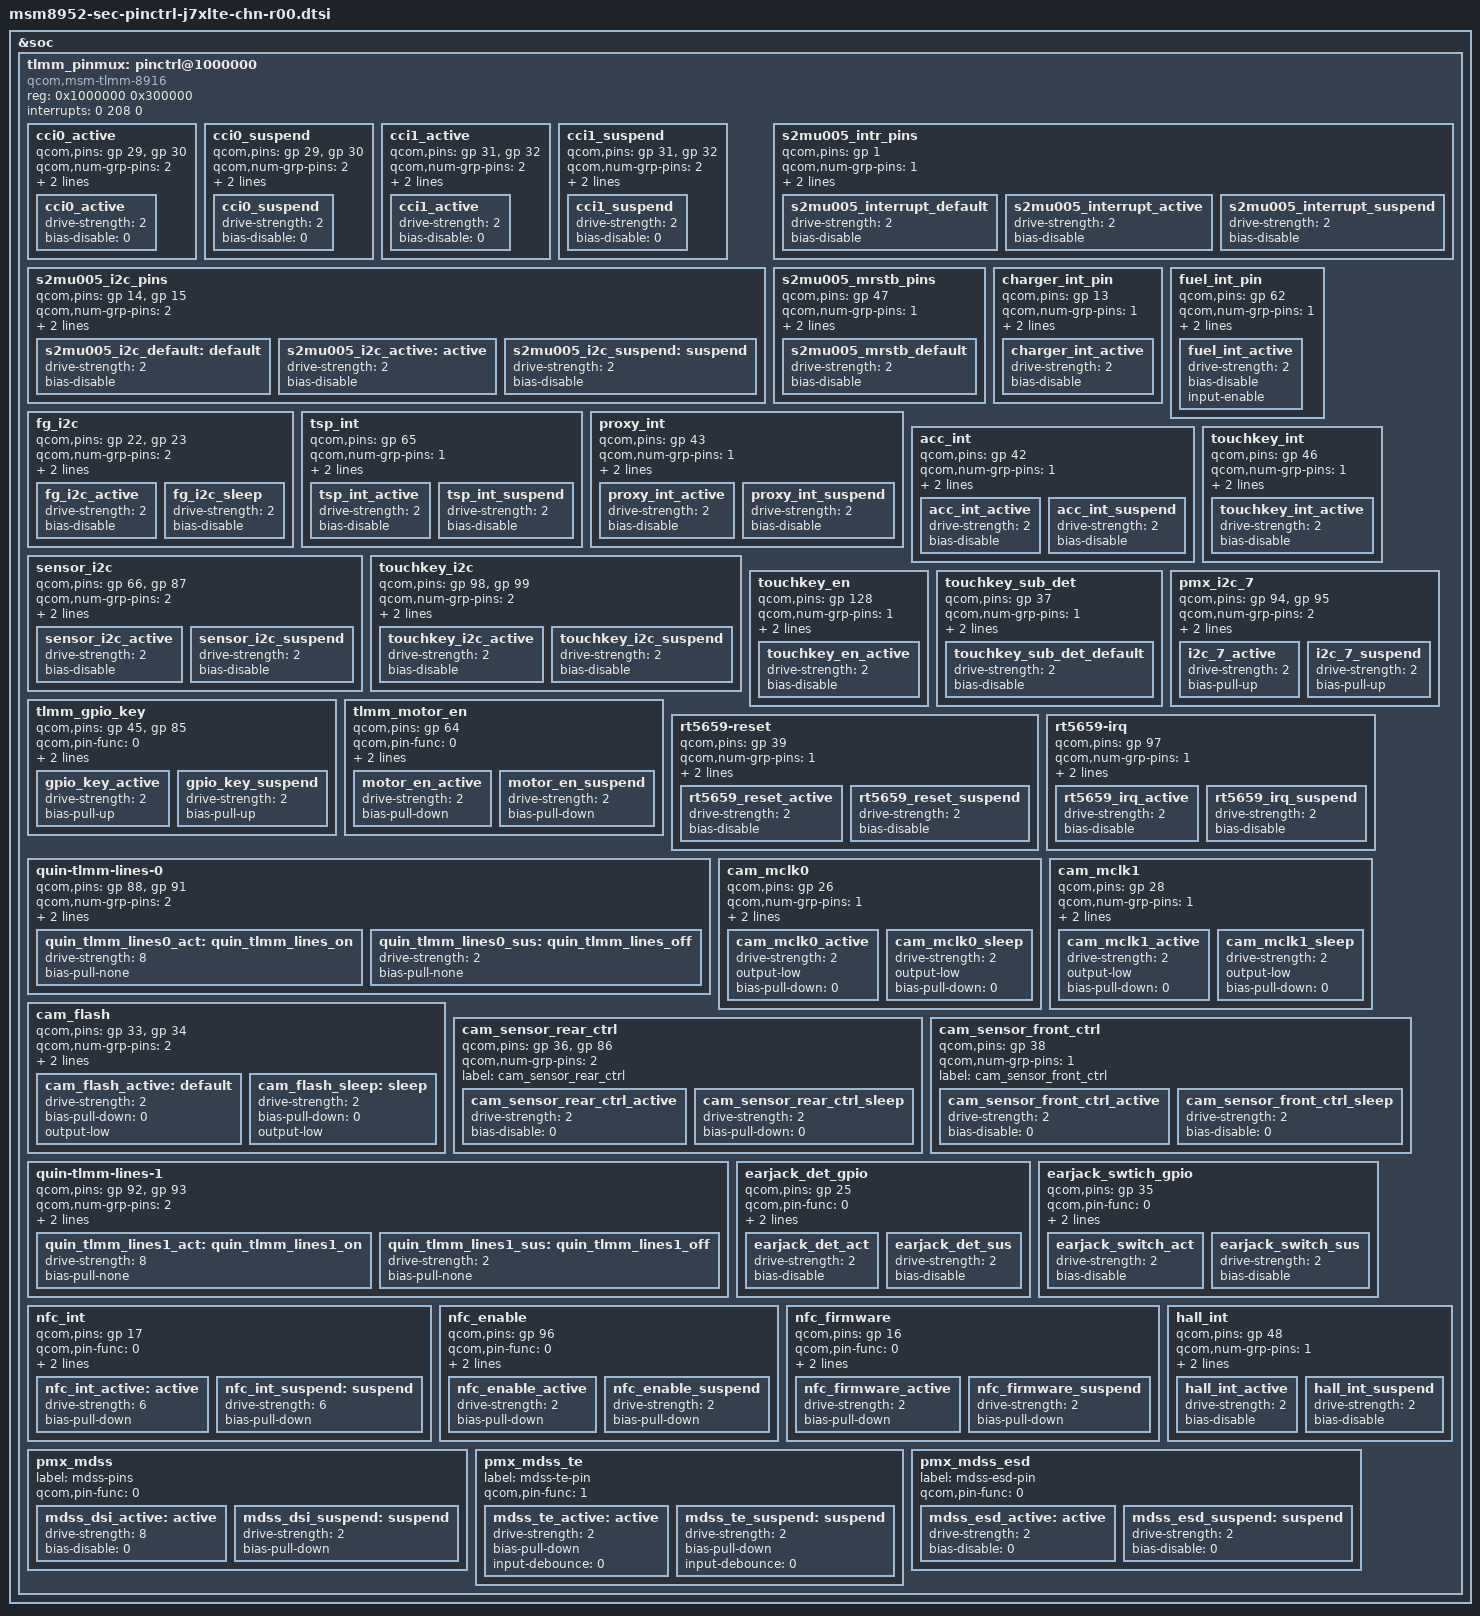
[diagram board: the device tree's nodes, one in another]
/*
 * Copyright (c) 2014-2015, The Linux Foundation. All rights reserved.
 *
 * This program is free software; you can redistribute it and/or modify
 * it under the terms of the GNU General Public License version 2 and
 * only version 2 as published by the Free Software Foundation.
 *
 * This program is distributed in the hope that it will be useful,
 * but WITHOUT ANY WARRANTY; without even the implied warranty of
 * MERCHANTABILITY or FITNESS FOR A PARTICULAR PURPOSE.  See the
 * GNU General Public License for more details.
 */

/* Pinctrl device tree file for j7xlte chn open REV0.0 */

&tlmm_pinmux {
	/* MUIC - S2MU005 */
	s2mu005_i2c_pins {
		qcom,pins = <&gp 14>, <&gp 15>; /* SDA, SCL */
		qcom,num-grp-pins = <2>;
		qcom,pin-func = <0>;
		label = "s2mu005_i2c_pins";
		s2mu005_i2c_default: default {
			drive-strength = <2>;
			bias-disable;
		};
		s2mu005_i2c_active: active {
			drive-strength = <2>;
			bias-disable;
		};
		s2mu005_i2c_suspend: suspend {
			drive-strength = <2>;
			bias-disable;
		};
	};

	s2mu005_intr_pins {
		qcom,pins = <&gp 1>;
		qcom,num-grp-pins = <1>;
		qcom,pin-func = <0>;
		label = "s2mu005_intr_pins";
		s2mu005_interrupt_default: s2mu005_interrupt_default {
			drive-strength = <2>;
			bias-disable;
		};
		s2mu005_interrupt_active: s2mu005_interrupt_active {
			drive-strength = <2>;
			bias-disable;
		};
		s2mu005_interrupt_suspend: s2mu005_interrupt_suspend {
			drive-strength = <2>;
			bias-disable;
		};
	};

	s2mu005_mrstb_pins {
		qcom,pins = <&gp 47>;
		qcom,num-grp-pins = <1>;
		qcom,pin-func = <0>;
		label = "s2mu005_mrstb_pins";
		s2mu005_mrstb_default: s2mu005_mrstb_default {
			drive-strength = <2>;
			bias-disable;
		};
	};

	charger_int_pin {
		qcom,pins = <&gp 13>;
		qcom,num-grp-pins = <1>;
		qcom,pin-func = <0>;
		label = "charger_int_gpio";
		charger_int_active: charger_int_active {
			drive-strength = <2>;
			bias-disable;         /* No PULL */
		};
	};

	fuel_int_pin {
		qcom,pins = <&gp 62>;
		qcom,num-grp-pins = <1>;
		qcom,pin-func = <0>;
		label = "fuel_int_gpio";
		fuel_int_active: fuel_int_active {
			drive-strength = <2>;
			bias-disable;         /* No PULL */
			input-enable;
		};
	};

	fg_i2c {
		/* CLK, DATA */
		qcom,pins = <&gp 22>, <&gp 23>;
		qcom,num-grp-pins = <2>;
		qcom,pin-func = <0>;
		label = "fg_i2c";

		fg_i2c_active: fg_i2c_active {
			drive-strength = <2>;	/* 2 MA */
			bias-disable; /* No PULL */
		};

		fg_i2c_sleep: fg_i2c_sleep {
			drive-strength = <2>;	/* 2 MA */
			bias-disable; /* No PULL */
		};
	};

	tsp_int {
		qcom,pins = <&gp 65>; /* INTERRUPT */
		qcom,num-grp-pins = <1>;
		qcom,pin-func = <0>;
		label = "tsp_int";
		tsp_int_active: tsp_int_active {
			drive-strength = <2>;
			bias-disable;
		};
		tsp_int_suspend: tsp_int_suspend {
			drive-strength = <2>;
			bias-disable;
		};
	};

	proxy_int {
		qcom,pins = <&gp 43>; /* INTERRUPT */
		qcom,num-grp-pins = <1>;
		qcom,pin-func = <3>;
		label = "proxy_int";
		proxy_int_active: proxy_int_active {
			drive-strength = <2>;
			bias-disable;
		};
		proxy_int_suspend: proxy_int_suspend {
			drive-strength = <2>;
			bias-disable;
		};
	};

	acc_int {
		qcom,pins = <&gp 42>; /* INTERRUPT */
		qcom,num-grp-pins = <1>;
		qcom,pin-func = <3>;
		label = "acc_int";
		acc_int_active: acc_int_active {
			drive-strength = <2>;
			bias-disable;
		};
		acc_int_suspend: acc_int_suspend {
			drive-strength = <2>;
			bias-disable;
		};
	};

	sensor_i2c {
		qcom,pins = <&gp 66>, <&gp 87>; /* SDA, SCL */
		qcom,num-grp-pins = <2>;
		qcom,pin-func = <0>;
		label = "sensor_i2c";
		sensor_i2c_active: sensor_i2c_active {
			drive-strength = <2>;
			bias-disable;
		};
		sensor_i2c_suspend: sensor_i2c_suspend {
			drive-strength = <2>;
			bias-disable;
		};
	};

	touchkey_int {
		qcom,pins = <&gp 46>; /* INTERRUPT */
		qcom,num-grp-pins = <1>;
		qcom,pin-func = <0>;
		label = "touchkey_int";
		touchkey_int_active: touchkey_int_active {
			drive-strength = <2>;
			bias-disable;
		};
	};

	touchkey_i2c {
		qcom,pins = <&gp 98>, <&gp 99>; /* SDA, SCL */
		qcom,num-grp-pins = <2>;
		qcom,pin-func = <0>;
		label = "touchkey_i2c";
		touchkey_i2c_active: touchkey_i2c_active {
			drive-strength = <2>;
			bias-disable;
		};
		touchkey_i2c_suspend: touchkey_i2c_suspend {
			drive-strength = <2>;
			bias-disable;
		};
	};

	touchkey_en {
		qcom,pins = <&gp 128>;
		qcom,num-grp-pins = <1>;
		qcom,pin-func = <0>;
		label = "touchkey_en";
		touchkey_en_active: touchkey_en_active {
			drive-strength = <2>;
			bias-disable;
		};
	};

	touchkey_sub_det {
		qcom,pins = <&gp 37>;
		qcom,num-grp-pins = <1>;
		qcom,pin-func = <0>;
		label = "touchkey_sub_det";
		touchkey_sub_det_default: touchkey_sub_det_default {
			drive-strength = <2>;
			bias-disable;
		};
	};

	tlmm_gpio_key {
		qcom,pins = <&gp 45>, <&gp 85>;
		qcom,pin-func = <0>;
		qcom,num-grp-pins = <2>;
		label = "tlmm_gpio_key";
		gpio_key_active: gpio_key_active {
			drive-strength = <2>;
			bias-pull-up;
		};
		gpio_key_suspend: gpio_key_suspend {
			drive-strength = <2>;
			bias-pull-up;
		};
	};

	tlmm_motor_en {
		qcom,pins = <&gp 64>;
		qcom,pin-func = <0>;
		qcom,num-grp-pins = <1>;
		label = "tlmm_motor_en";
		motor_en_active: motor_en_active {
			drive-strength = <2>;
			bias-pull-down;
		};
		motor_en_suspend: motor_en_suspend {
			drive-strength = <2>;
			bias-pull-down;
		};
	};
	
	pmx_i2c_7 {
		/* CLK, DATA */
		qcom,pins = <&gp 94>, <&gp 95>;
		qcom,num-grp-pins = <2>;
		qcom,pin-func = <4>;
		label = "pmx_i2c_7";
		/* active state */
		i2c_7_active: i2c_7_active{
			drive-strength = <2>;
			bias-pull-up;
		};
		/* suspend state */
		i2c_7_suspend: i2c_7_suspend {
			drive-strength = <2>;
			bias-pull-up;
		};
	};

	rt5659-reset {
		qcom,pins = <&gp 39>;
		qcom,num-grp-pins = <1>;
		qcom,pin-func = <0>;
		label = "rt5659-reset";
		rt5659_reset_active: rt5659_reset_active {
			drive-strength = <2>;
			bias-disable;
		};
		rt5659_reset_suspend: rt5659_reset_suspend {
			drive-strength = <2>;
			bias-disable;
		};
	};
	
	rt5659-irq {
		qcom,pins = <&gp 97>;
		qcom,num-grp-pins = <1>;
		qcom,pin-func = <0>;
		label = "rt5659-irq";
		rt5659_irq_active: rt5659_irq_active {
			drive-strength = <2>;
			bias-disable;
		};
		rt5659_irq_suspend: rt5659_irq_suspend {
			drive-strength = <2>;
			bias-disable;
		};
	};		
	
	quin-tlmm-lines-0 {
		qcom,pins = <&gp 88>, <&gp 91>;
		qcom,num-grp-pins = <2>;
		qcom,pin-func = <1>;
		label = "quin-lines-0";
		quin_tlmm_lines0_act: quin_tlmm_lines_on {
			drive-strength = <8>;
			bias-pull-none;
		};
		quin_tlmm_lines0_sus: quin_tlmm_lines_off {
			drive-strength = <2>;
			bias-pull-none;
		};
	};

	cam_mclk0 {
		qcom,pins = <&gp 26>;
		qcom,num-grp-pins = <1>;
		qcom,pin-func = <1>;
		label = "cam_mclk0";
		cam_mclk0_active: cam_mclk0_active {
			drive-strength = <2>;
			output-low;
			bias-pull-down=<0>;
		};
		cam_mclk0_sleep: cam_mclk0_sleep {
			drive-strength = <2>;
			output-low;
			bias-pull-down=<0>;
		};
	};


	cam_flash {
		qcom,pins = <&gp 33>, <&gp 34>;
		qcom,num-grp-pins = <2>;
		qcom,pin-func = <0>;
		label = "cam_flash";

		cam_flash_active: default {
			drive-strength = <2>;	/* 2 MA */
			bias-pull-down = <0>; /* PULL DOWN */
			output-low;
		};
		cam_flash_sleep: sleep {
			drive-strength = <2>;	/* 2 MA */
			bias-pull-down = <0>; /* PULL DOWN */
			output-low;
		};
	};

	cam_sensor_rear_ctrl {
		qcom,pins = <&gp 36>, <&gp 86>;
		qcom,num-grp-pins = <2>;
		label = "cam_sensor_rear_ctrl";
		cam_sensor_rear_ctrl_active: cam_sensor_rear_ctrl_active {
			drive-strength = <2>;
			bias-disable = <0>;
		};
		cam_sensor_rear_ctrl_sleep: cam_sensor_rear_ctrl_sleep {
			drive-strength = <2>;
			bias-pull-down = <0>;
		};
	};

	cam_mclk1 {
		qcom,pins = <&gp 28>;
		qcom,num-grp-pins = <1>;
		qcom,pin-func = <1>;
		label = "cam_mclk1";
		cam_mclk1_active: cam_mclk1_active {
			drive-strength = <2>;
			output-low;
			bias-pull-down = <0>;
		};
		cam_mclk1_sleep: cam_mclk1_sleep {
			drive-strength = <2>;
			output-low;
			bias-pull-down = <0>;
		};
	};

	cam_sensor_front_ctrl {
		qcom,pins = <&gp 38>;
		qcom,num-grp-pins = <1>;
		label = "cam_sensor_front_ctrl";
		cam_sensor_front_ctrl_active: cam_sensor_front_ctrl_active {
			drive-strength = <2>;
			bias-disable = <0>;
		};
		cam_sensor_front_ctrl_sleep: cam_sensor_front_ctrl_sleep {
			drive-strength = <2>;
			bias-disable = <0>; 
		};
	};
	
	quin-tlmm-lines-1 {
		qcom,pins = <&gp 92>, <&gp 93>;
		qcom,num-grp-pins = <2>;
		qcom,pin-func = <3>;
		label = "quin-lines-1";
		quin_tlmm_lines1_act: quin_tlmm_lines1_on {
			drive-strength = <8>;
			bias-pull-none;
		};
		quin_tlmm_lines1_sus: quin_tlmm_lines1_off {
			drive-strength = <2>;
			bias-pull-none;
		};
	};
	/delete-node/ tpiu_seta_18;
	/delete-node/ pri-tlmm-lines;

	earjack_det_gpio {
		  qcom,pins = <&gp 25>;
		  qcom,pin-func = <0>;
		  qcom,num-grp-pins = <1>;
		  label = "earjack_det_gpio";
		  earjack_det_act: earjack_det_act {
				drive-strength = <2>;
				bias-disable;
		  };
		  earjack_det_sus: earjack_det_sus {
				drive-strength = <2>;
				bias-disable;
		  };
	};
	earjack_swtich_gpio {
		  qcom,pins = <&gp 35>;
		  qcom,pin-func = <0>;
		  qcom,num-grp-pins = <1>;
		  label = "earjack_swtich_gpio";
		  earjack_switch_act: earjack_switch_act {
				drive-strength = <2>;
				bias-disable;
		  };
		  earjack_switch_sus: earjack_switch_sus {
				drive-strength = <2>;
				bias-disable;
		  };
	};

	/delete-node/ pmx_rd_nfc_int;
	nfc_int {
		qcom,pins = <&gp 17>;
		qcom,pin-func = <0>;
		qcom,num-grp-pins = <1>;
		label = "pmx_nfc_int";

		nfc_int_active: active {
			drive-strength = <6>;
			bias-pull-down;
		};

		nfc_int_suspend: suspend {
			drive-strength = <6>;
			bias-pull-down;
		};
	};

	nfc_enable {
		qcom,pins = <&gp 96>;
		qcom,pin-func = <0>;
		qcom,num-grp-pins = <1>;
		label = "nfc_enable";

		nfc_enable_active: nfc_enable_active {
			drive-strength = <2>;
			bias-pull-down; /* PULL DOWN */
		};
		nfc_enable_suspend: nfc_enable_suspend {
			drive-strength = <2>;
			bias-pull-down; /* PULL DOWN */
		};
	};

	nfc_firmware {
		qcom,pins = <&gp 16>;
		qcom,pin-func = <0>;
		qcom,num-grp-pins = <1>;
		label = "nfc_firmware";

		nfc_firmware_active: nfc_firmware_active {
			drive-strength = <2>;
			bias-pull-down; /* PULL DOWN */
		};

		nfc_firmware_suspend: nfc_firmware_suspend {
			drive-strength = <2>;
			bias-pull-down; /* PULL DOWN */
		};
	};

	hall_int {
                qcom,pins = <&gp 48>; /* INTERRUPT */
                qcom,num-grp-pins = <1>;
                qcom,pin-func = <0>;
                label = "hall_int";
                hall_int_active: hall_int_active {
			drive-strength = <2>;
                        bias-disable;
                };
                hall_int_suspend: hall_int_suspend {
			drive-strength = <2>;
                        bias-disable;
                };
        };

	pmx_mdss: pmx_mdss {			// GPIO 41 & 61
		label = "mdss-pins";
		qcom,pin-func = <0>;
		mdss_dsi_active: active {
			drive-strength = <8>;
			bias-disable = <0>;	// no pull
		};
		mdss_dsi_suspend: suspend {
			drive-strength = <2>;
			bias-pull-down;
		};
	};

	pmx_mdss_te: pmx_mdss_te {		// GPIO 24
		label = "mdss-te-pin";
		qcom,pin-func = <1>;
		mdss_te_active: active {
			drive-strength = <2>;
			bias-pull-down;
			input-debounce = <0>;
		};
		mdss_te_suspend: suspend {
			drive-strength = <2>;
			bias-pull-down;
			input-debounce = <0>;
		};
	};

	pmx_mdss_esd: pmx_mdss_esd {		// GPIO 13 & 54
		label = "mdss-esd-pin";
		qcom,pin-func = <0>;
		mdss_esd_active: active {
			drive-strength = <2>;
			bias-disable = <0>;	// no pull
		};
		mdss_esd_suspend: suspend {
			drive-strength = <2>;
			bias-disable = <0>;	// no pull
		};
	};
};

&soc {
	tlmm_pinmux: pinctrl@1000000 {
		compatible = "qcom,msm-tlmm-8916";
		reg = <0x1000000 0x300000>;
		interrupts = <0 208 0>;

		/* cci */
		cci0_active {
			/* CLK, DATA */
			qcom,pins = <&gp 29>, <&gp 30>;
			qcom,num-grp-pins = <2>;
			qcom,pin-func = <1>;
			label = "cci0-active";
			/* active state */
			cci0_active: cci0_active {
				drive-strength = <2>; /* 2 MA */
				bias-disable = <0>; /* No PULL */
			};
		};

		cci0_suspend {
			/* CLK, DATA */
			qcom,pins = <&gp 29>, <&gp 30>;
			qcom,num-grp-pins = <2>;
			qcom,pin-func = <0>;
			label = "cci0-suspend";
			/*suspended state */
			cci0_suspend: cci0_suspend {
				drive-strength = <2>; /* 2 MA */
				bias-disable = <0>; /* No PULL */
			};
		};

		cci1_active {
			/* CLK, DATA */
			qcom,pins = <&gp 31>, <&gp 32>;
			qcom,num-grp-pins = <2>;
			qcom,pin-func = <1>;
			label = "cci1-active";
			/* active state */
			cci1_active: cci1_active {
				drive-strength = <2>; /* 2 MA */
				bias-disable=<0>; /* No PULL */
			};
		};

		cci1_suspend {
			/* CLK, DATA */
			qcom,pins = <&gp 31>, <&gp 32>;
			qcom,num-grp-pins = <2>;
			qcom,pin-func = <0>;
			label = "cci1-suspend";
			/*suspended state */
			cci1_suspend: cci1_suspend {
				drive-strength = <2>; /* 2 MA */
				bias-disable=<0>; /* No PULL */
			};
		};
	};
};
